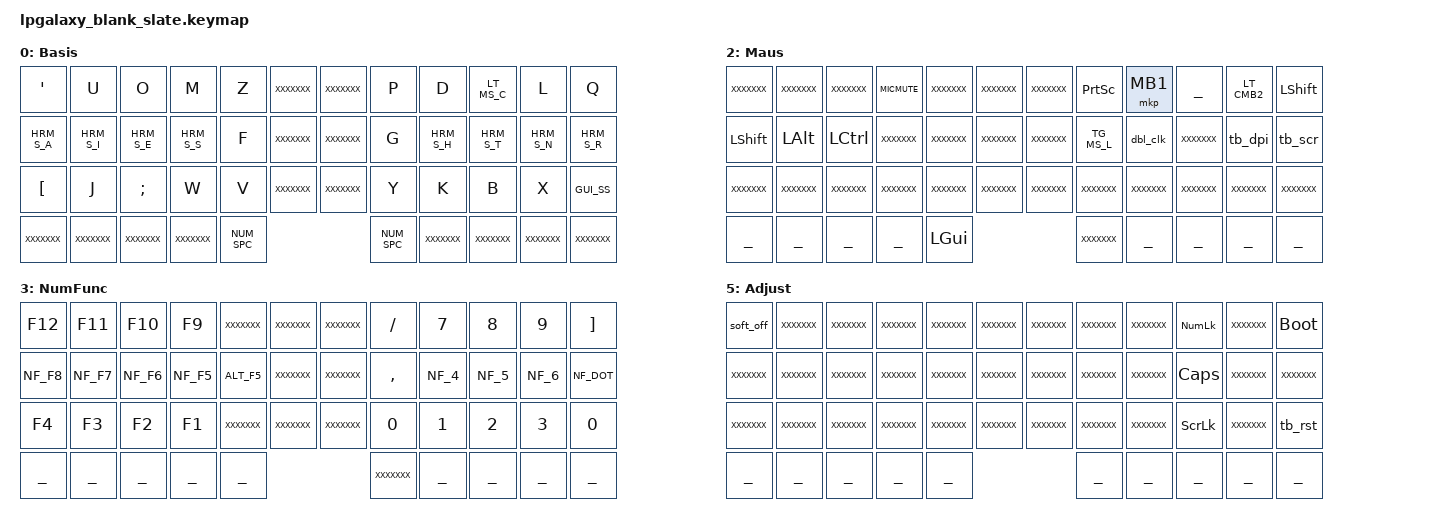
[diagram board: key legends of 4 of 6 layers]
 /*
 * Copyright (c) 2022 Pete Johanson
 *
 * SPDX-License-Identifier: MIT
 */

#include <dt-bindings/zmk/outputs.h>

/*                KEY POSITIONS

    ╭─────────────────────────────────────────────────╮
    │  0   1   2   3   4 │  5  6 │  7   8   9  10  11 │
    │ 12  13  14  15  16 │ 17 18 │ 19  20  21  22  23 │
    │ 24  25  26  27  28 │ 29 30 │ 31  32  33  34  35 │
    │ 36  37  38  39 │  40   │   41  │ 42  43  44  45 │
    ╰─────────────────────────────────────────────────╯
*/

#define COMBO_ESC       0 1
#define COMBO_DOT       14 15
#define COMBO_COMMA     13 14
#define COMBO_DASH      12 13
#define COMBO_SQUOT     2 3
#define COMBO_DQUOT     26 27
#define COMBO_STAR      14 27
#define COMBO_HASH      25 26
#define COMBO_EQUAL     1 2
#define COMBO_PERCENT   15 26
#define COMBO_SLASH     14 25
#define COMBO_BACKSLASH 13 26
#define COMBO_BSPC      20 21
#define COMBO_BSPC_WORD 20 21 22
#define COMBO_DEL       22 23
#define COMBO_DEL_WORD  21 22 23
#define COMBO_COPY      8 9
#define COMBO_PASTE     9 10
#define COMBO_CUT       10 11
#define COMBO_COPY_ALL  32 33
#define COMBO_COPY_LINE 33 34
#define COMBO_COPY_WORD 34 35
#define COMBO_ALT_F4    19 31
#define COMBO_TAB       21 32
#define COMBO_ENTER     21 22
#define COMBO_VDPR      8 20
#define COMBO_VDNX      9 21
#define COMBO_CAPS_WORD 12 23
#define COMBO_NUM_WORD  20 33
#define COMBO_SOFT_OFF  24 35

#include "mrsnoot_base.dtsi"
#include "mrsnoot_combos.dtsi"
#include "mrsnoot_macros.dtsi"

/ {
    keymap {
        compatible = "zmk,keymap";

        base_layer {
            display-name = "Basis";
            bindings = <
&kp QUOT   &kp U      &kp O      &kp M      &kp Z      XXXXXXX    XXXXXXX    &kp P      &kp D      LT_MS_C    &kp L      &kp Q
HRM_S_A    HRM_S_I    HRM_S_E    HRM_S_S    &kp F      XXXXXXX    XXXXXXX    &kp G      HRM_S_H    HRM_S_T    HRM_S_N    HRM_S_R
&kp LBKT   &kp J      &kp SEMI   &kp W      &kp V      XXXXXXX    XXXXXXX    &kp Y      &kp K      &kp B      &kp X      GUI_SS 
XXXXXXX    XXXXXXX    XXXXXXX    XXXXXXX    NUM_SPC                          NUM_SPC    XXXXXXX    XXXXXXX    XXXXXXX    XXXXXXX
            >;
        };

        nav_layer {
            display-name = "Navi";
            bindings = <
&bt BT_CLR XXXXXXX    XXXXXXX    XXXXXXX    XXXXXXX    XXXXXXX    XXXXXXX    XXXXXXX    &kp HOME   &kp UP     &kp END    &kp PG_UP
&kp LSHFT  &kp LALT   &kp LCTRL  _______    XXXXXXX    XXXXXXX    XXXXXXX    XXXXXXX    &kp LEFT   &kp DOWN   &kp RIGHT  &kp PG_DN
XXXXXXX    XXXXXXX    XXXXXXX    XXXXXXX    XXXXXXX    XXXXXXX    XXXXXXX    &bt BT(0)  &bt BT(1)  &bt BT(2)  &bt BT(3)  &bt BT(4)
_______    _______    _______    _______    &kp LGUI                         _______    _______    _______    _______    _______
            >;
        };

        mouse_layer {
            display-name = "Maus";
            bindings = <
XXXXXXX    XXXXXXX    XXXXXXX    MICMUTE    XXXXXXX    XXXXXXX    XXXXXXX    &kp PSCRN  &mkp MB1   _______    LT_CMB2    &kp LSHFT
&kp LSHFT  &kp LALT   &kp LCTRL  XXXXXXX    XXXXXXX    XXXXXXX    XXXXXXX    TG_MS_L    &dbl_clk   XXXXXXX    &tb_dpi    &tb_scr
XXXXXXX    XXXXXXX    XXXXXXX    XXXXXXX    XXXXXXX    XXXXXXX    XXXXXXX    XXXXXXX    XXXXXXX    XXXXXXX    XXXXXXX    XXXXXXX
_______    _______    _______    _______    &kp LGUI                         XXXXXXX    _______    _______    _______    _______
            >;
        };

        num_func_layer {
            display-name = "NumFunc";
            bindings = <
&kp F12    &kp F11    &kp F10    &kp F9     XXXXXXX    XXXXXXX    XXXXXXX    &kp SLASH  &kp N7     &kp N8     &kp N9     &kp RBKT
NF_F8      NF_F7      NF_F6      NF_F5      ALT_F5     XXXXXXX    XXXXXXX    &kp COMMA  NF_4       NF_5       NF_6       NF_DOT
&kp F4     &kp F3     &kp F2     &kp F1     XXXXXXX    XXXXXXX    XXXXXXX    &kp N0     &kp N1     &kp N2     &kp N3     &kp N0
_______    _______    _______    _______    _______                          XXXXXXX    _______    _______    _______    _______
            >;
        };

        symbol_layer {
            display-name = "Symbol";
            bindings = <
DE_EXLM    DE_DEG     DE_SECT    DE_DLR     DE_AMPR    XXXXXXX    XXXXXXX    XXXXXXX    XXXXXXX    NP_XMLL    NP_XMLF    DE_PIPE
DE_QUES    DE_LCBR    DE_RCBR    DE_LPRN    DE_RPRN    XXXXXXX    XXXXXXX    XXXXXXX    _______    &f2_cpln   &im1_ins   DE_CIRC
XXXXXXX    DE_LBRC    DE_RBRC    DE_LABK    DE_RABK    XXXXXXX    XXXXXXX    XXXXXXX    XXXXXXX    DE_ACUT    DE_GRV     DE_TILD
_______    _______    _______    _______    &mo ADJ_L                        _______    _______    _______    _______    _______
            >;
        };

        adjust_layer {
            display-name = "Adjust";
            bindings = <
&soft_off  XXXXXXX    XXXXXXX    XXXXXXX    XXXXXXX    XXXXXXX    XXXXXXX    XXXXXXX    XXXXXXX    &kp KP_NLCK XXXXXXX   &bootloader
XXXXXXX    XXXXXXX    XXXXXXX    XXXXXXX    XXXXXXX    XXXXXXX    XXXXXXX    XXXXXXX    XXXXXXX    &kp CLCK    XXXXXXX   XXXXXXX
XXXXXXX    XXXXXXX    XXXXXXX    XXXXXXX    XXXXXXX    XXXXXXX    XXXXXXX    XXXXXXX    XXXXXXX    &kp SLCK    XXXXXXX   &tb_rst
_______    _______    _______    _______    _______                          _______    _______    _______     _______   _______
            >;
        };
    };
};

